# FRAM_3 register map
Vendor: Texas Instruments
Peripheral module from a debugger description file (folder msp430).
Registers are 16-bit, read-write, reset 0x0 unless marked. A register's access mark holds for its fields unless they carry their own. Offsets are as the file gives them; lines under a group give offsets from that group; [hi:lo] are bit positions; {n}, {i} and the like mark numbered series; 'fields as' and 'values as' point back to an identical list; <NAME> marks a mode.

## FRAM
0x1A0 FRCTL0 — FRAM Controller Control 0
  [6:4] NWAITS — FRAM Wait state control Bit: 0
    {v}=FRAM Wait state control: {v} (v=0..7)
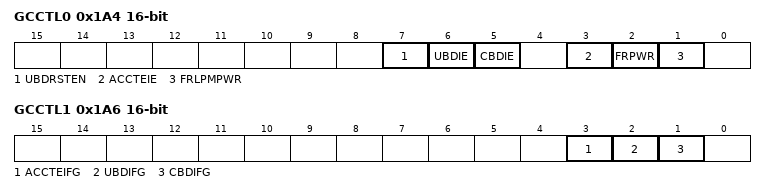
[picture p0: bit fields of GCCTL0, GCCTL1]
0x1A4 GCCTL0 — General Control 0
  [7] UBDRSTEN — Enable Power Up Clear (PUC) reset if FRAM uncorrectable bit error detected
  [6] UBDIE — Enable NMI event if uncorrectable bit error detected
  [5] CBDIE — Enable NMI event if correctable bit error detected
  [3] ACCTEIE — RESERVED
  [2] FRPWR — FRAM Power Control
  [1] FRLPMPWR — FRAM Enable FRAM auto power up after LPM
0x1A6 GCCTL1 — General Control 1
  [3] ACCTEIFG — Access time error flag
  [2] UBDIFG — FRAM uncorrectable bit error flag
  [1] CBDIFG — FRAM correctable bit error flag
